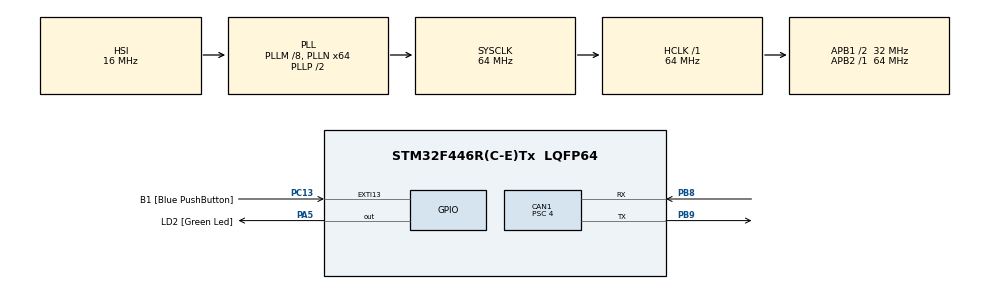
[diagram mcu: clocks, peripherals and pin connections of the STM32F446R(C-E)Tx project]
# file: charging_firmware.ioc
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CAN1.BS1=CAN_BS1_8TQ
CAN1.BS2=CAN_BS2_7TQ
CAN1.CalculateTimeBit=2000
CAN1.CalculateTimeQuantum=125.0
CAN1.Prescaler=4
Mcu.Family=STM32F4
Mcu.Name=STM32F446R(C-E)Tx
Mcu.Package=LQFP64
NVIC.CAN1_RX0_IRQn=true\:0\:0\:false\:false\:true\:true
NVIC.PriorityGroup=NVIC_PRIORITYGROUP_0
NVIC.TIM2_IRQn=true\:0\:0\:false\:false\:true\:true
PA13.GPIO_Label=TMS
PA13.Signal=SYS_JTMS-SWDIO
PA14.GPIO_Label=TCK
PA14.Signal=SYS_JTCK-SWCLK
PA2.GPIO_Label=USART_TX
PA2.Signal=USART2_TX
PA3.GPIO_Label=USART_RX
PA3.Signal=USART2_RX
PA5.GPIO_Label=LD2 [Green Led]
PA5.Signal=GPIO_Output
PB3.GPIO_Label=SWO
PB3.Signal=SYS_JTDO-SWO
PB8.Mode=Master
PB8.Signal=CAN1_RX
PB9.Mode=Master
PB9.Signal=CAN1_TX
PC13.GPIO_Label=B1 [Blue PushButton]
PC13.GPIO_ModeDefaultEXTI=GPIO_MODE_IT_FALLING
PC13.Signal=GPXTI13
PC14-OSC32_IN.Signal=RCC_OSC32_IN
PC15-OSC32_OUT.Signal=RCC_OSC32_OUT
PH0-OSC_IN.Signal=RCC_OSC_IN
PH1-OSC_OUT.Signal=RCC_OSC_OUT
ProjectManager.HeapSize=0x200
ProjectManager.StackSize=0x400
ProjectManager.TargetToolchain=SW4STM32
RCC.AHBFreq_Value=64000000
RCC.APB1CLKDivider=RCC_HCLK_DIV2
RCC.APB1Freq_Value=32000000
RCC.APB1TimFreq_Value=64000000
RCC.APB2Freq_Value=64000000
RCC.APB2TimFreq_Value=64000000
RCC.CortexFreq_Value=64000000
RCC.FLatency-AdvancedSettings=FLASH_LATENCY_2
RCC.HCLKFreq_Value=64000000
RCC.HSE_VALUE=8000000
RCC.HSI_VALUE=16000000
RCC.LSE_VALUE=32768
RCC.PLLM=8
RCC.PLLN=64
RCC.SYSCLKFreq_VALUE=64000000
RCC.SYSCLKSource=RCC_SYSCLKSOURCE_PLLCLK
RCC.USBFreq_Value=64000000
RCC.VCOOutputFreq_Value=128000000
TIM2.Period=49999
TIM2.Prescaler=6399
VP_TIM2_VS_ClockSourceINT.Mode=Internal
board=NUCLEO-F446RE

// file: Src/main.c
/**
  ******************************************************************************
  * File Name          : main.c
  * Description        : Main program body
  ******************************************************************************
  ** This notice applies to any and all portions of this file
  * that are not between comment pairs USER CODE BEGIN and
  * USER CODE END. Other portions of this file, whether
  * inserted by the user or by software development tools
  * are owned by their respective copyright owners.
  *
  * COPYRIGHT(c) 2017 STMicroelectronics
  *
  * Redistribution and use in source and binary forms, with or without modification,
  * are permitted provided that the following conditions are met:
  *   1. Redistributions of source code must retain the above copyright notice,
  *      this list of conditions and the following disclaimer.
  *   2. Redistributions in binary form must reproduce the above copyright notice,
  *      this list of conditions and the following disclaimer in the documentation
  *      and/or other materials provided with the distribution.
  *   3. Neither the name of STMicroelectronics nor the names of its contributors
  *      may be used to endorse or promote products derived from this software
  *      without specific prior written permission.
  *
  * THIS SOFTWARE IS PROVIDED BY THE COPYRIGHT HOLDERS AND CONTRIBUTORS "AS IS"
  * AND ANY EXPRESS OR IMPLIED WARRANTIES, INCLUDING, BUT NOT LIMITED TO, THE
  * IMPLIED WARRANTIES OF MERCHANTABILITY AND FITNESS FOR A PARTICULAR PURPOSE ARE
  * DISCLAIMED. IN NO EVENT SHALL THE COPYRIGHT HOLDER OR CONTRIBUTORS BE LIABLE
  * FOR ANY DIRECT, INDIRECT, INCIDENTAL, SPECIAL, EXEMPLARY, OR CONSEQUENTIAL
  * DAMAGES (INCLUDING, BUT NOT LIMITED TO, PROCUREMENT OF SUBSTITUTE GOODS OR
  * SERVICES; LOSS OF USE, DATA, OR PROFITS; OR BUSINESS INTERRUPTION) HOWEVER
  * CAUSED AND ON ANY THEORY OF LIABILITY, WHETHER IN CONTRACT, STRICT LIABILITY,
  * OR TORT (INCLUDING NEGLIGENCE OR OTHERWISE) ARISING IN ANY WAY OUT OF THE USE
  * OF THIS SOFTWARE, EVEN IF ADVISED OF THE POSSIBILITY OF SUCH DAMAGE.
  *
  ******************************************************************************
  */

#include "main.h"
#include "stm32f4xx_hal.h"

/* USER CODE BEGIN Includes */
#include "debug.h"
#include "can.h"
#include "temp.h"
/* USER CODE END Includes */

CAN_HandleTypeDef hcan1;

TIM_HandleTypeDef htim2;

/* USER CODE BEGIN PV */
/* Private variables ---------------------------------------------------------*/

/* USER CODE END PV */

void SystemClock_Config(void);
static void MX_GPIO_Init(void);
static void MX_CAN1_Init(void);
static void MX_TIM2_Init(void);

/* USER CODE BEGIN PFP */
/* Private function prototypes -----------------------------------------------*/

/* USER CODE END PFP */

int main(void)
{

  /* MCU Configuration----------------------------------------------------------*/

  /* Reset of all peripherals, Initializes the Flash interface and the Systick. */
  HAL_Init();

  /* Configure the system clock */
  SystemClock_Config();

  /* Initialize all configured peripherals */
  MX_GPIO_Init();
  MX_CAN1_Init();
  MX_TIM2_Init();

  /* USER CODE BEGIN 2 */
  debug_init();
  can_recieve_init();
  temp_init();
  /* USER CODE END 2 */

  /* Infinite loop */
  while (1)
  {

  /* USER CODE BEGIN 3 */
	  HAL_GPIO_TogglePin(LD2_GPIO_Port, LD2_Pin);
	  HAL_Delay(1000);
	  // can_test();
  }
  /* USER CODE END 3 */

}

/** System Clock Configuration
*/
void SystemClock_Config(void)
{

  RCC_OscInitTypeDef RCC_OscInitStruct;
  RCC_ClkInitTypeDef RCC_ClkInitStruct;

    /**Configure the main internal regulator output voltage
    */
  __HAL_RCC_PWR_CLK_ENABLE();

  __HAL_PWR_VOLTAGESCALING_CONFIG(PWR_REGULATOR_VOLTAGE_SCALE3);

    /**Initializes the CPU, AHB and APB busses clocks
    */
  RCC_OscInitStruct.OscillatorType = RCC_OSCILLATORTYPE_HSI;
  RCC_OscInitStruct.HSIState = RCC_HSI_ON;
  RCC_OscInitStruct.HSICalibrationValue = 16;
  RCC_OscInitStruct.PLL.PLLState = RCC_PLL_ON;
  RCC_OscInitStruct.PLL.PLLSource = RCC_PLLSOURCE_HSI;
  RCC_OscInitStruct.PLL.PLLM = 8;
  RCC_OscInitStruct.PLL.PLLN = 64;
  RCC_OscInitStruct.PLL.PLLP = RCC_PLLP_DIV2;
  RCC_OscInitStruct.PLL.PLLQ = 2;
  RCC_OscInitStruct.PLL.PLLR = 2;
  if (HAL_RCC_OscConfig(&RCC_OscInitStruct) != HAL_OK)
  {
    _Error_Handler(__FILE__, __LINE__);
  }

    /**Initializes the CPU, AHB and APB busses clocks
    */
  RCC_ClkInitStruct.ClockType = RCC_CLOCKTYPE_HCLK|RCC_CLOCKTYPE_SYSCLK
                              |RCC_CLOCKTYPE_PCLK1|RCC_CLOCKTYPE_PCLK2;
  RCC_ClkInitStruct.SYSCLKSource = RCC_SYSCLKSOURCE_PLLCLK;
  RCC_ClkInitStruct.AHBCLKDivider = RCC_SYSCLK_DIV1;
  RCC_ClkInitStruct.APB1CLKDivider = RCC_HCLK_DIV2;
  RCC_ClkInitStruct.APB2CLKDivider = RCC_HCLK_DIV1;

  if (HAL_RCC_ClockConfig(&RCC_ClkInitStruct, FLASH_LATENCY_2) != HAL_OK)
  {
    _Error_Handler(__FILE__, __LINE__);
  }

    /**Configure the Systick interrupt time
    */
  HAL_SYSTICK_Config(HAL_RCC_GetHCLKFreq()/1000);

    /**Configure the Systick
    */
  HAL_SYSTICK_CLKSourceConfig(SYSTICK_CLKSOURCE_HCLK);

  /* SysTick_IRQn interrupt configuration */
  HAL_NVIC_SetPriority(SysTick_IRQn, 0, 0);
}

/* CAN1 init function */
static void MX_CAN1_Init(void)
{

  hcan1.Instance = CAN1;
  hcan1.Init.Prescaler = 4;
  hcan1.Init.Mode = CAN_MODE_NORMAL;
  hcan1.Init.SJW = CAN_SJW_1TQ;
  hcan1.Init.BS1 = CAN_BS1_8TQ;
  hcan1.Init.BS2 = CAN_BS2_7TQ;
  hcan1.Init.TTCM = DISABLE;
  hcan1.Init.ABOM = DISABLE;
  hcan1.Init.AWUM = DISABLE;
  hcan1.Init.NART = DISABLE;
  hcan1.Init.RFLM = DISABLE;
  hcan1.Init.TXFP = DISABLE;
  if (HAL_CAN_Init(&hcan1) != HAL_OK)
  {
    _Error_Handler(__FILE__, __LINE__);
  }

}

/* TIM2 init function */
static void MX_TIM2_Init(void)
{

  TIM_ClockConfigTypeDef sClockSourceConfig;
  TIM_MasterConfigTypeDef sMasterConfig;

  htim2.Instance = TIM2;
  htim2.Init.Prescaler = 6399;
  htim2.Init.CounterMode = TIM_COUNTERMODE_UP;
  htim2.Init.Period = 49999;
  htim2.Init.ClockDivision = TIM_CLOCKDIVISION_DIV1;
  if (HAL_TIM_Base_Init(&htim2) != HAL_OK)
  {
    _Error_Handler(__FILE__, __LINE__);
  }

  sClockSourceConfig.ClockSource = TIM_CLOCKSOURCE_INTERNAL;
  if (HAL_TIM_ConfigClockSource(&htim2, &sClockSourceConfig) != HAL_OK)
  {
    _Error_Handler(__FILE__, __LINE__);
  }

  sMasterConfig.MasterOutputTrigger = TIM_TRGO_RESET;
  sMasterConfig.MasterSlaveMode = TIM_MASTERSLAVEMODE_DISABLE;
  if (HAL_TIMEx_MasterConfigSynchronization(&htim2, &sMasterConfig) != HAL_OK)
  {
    _Error_Handler(__FILE__, __LINE__);
  }

}

/** Configure pins as
        * Analog
        * Input
        * Output
        * EVENT_OUT
        * EXTI
     PA2   ------> USART2_TX
     PA3   ------> USART2_RX
*/
static void MX_GPIO_Init(void)
{

  GPIO_InitTypeDef GPIO_InitStruct;

  /* GPIO Ports Clock Enable */
  __HAL_RCC_GPIOC_CLK_ENABLE();
  __HAL_RCC_GPIOH_CLK_ENABLE();
  __HAL_RCC_GPIOA_CLK_ENABLE();
  __HAL_RCC_GPIOB_CLK_ENABLE();

  /*Configure GPIO pin Output Level */
  HAL_GPIO_WritePin(LD2_GPIO_Port, LD2_Pin, GPIO_PIN_RESET);

  /*Configure GPIO pin : B1_Pin */
  GPIO_InitStruct.Pin = B1_Pin;
  GPIO_InitStruct.Mode = GPIO_MODE_IT_FALLING;
  GPIO_InitStruct.Pull = GPIO_NOPULL;
  HAL_GPIO_Init(B1_GPIO_Port, &GPIO_InitStruct);

  /*Configure GPIO pins : USART_TX_Pin USART_RX_Pin */
  GPIO_InitStruct.Pin = USART_TX_Pin|USART_RX_Pin;
  GPIO_InitStruct.Mode = GPIO_MODE_AF_PP;
  GPIO_InitStruct.Pull = GPIO_NOPULL;
  GPIO_InitStruct.Speed = GPIO_SPEED_FREQ_VERY_HIGH;
  GPIO_InitStruct.Alternate = GPIO_AF7_USART2;
  HAL_GPIO_Init(GPIOA, &GPIO_InitStruct);

  /*Configure GPIO pin : LD2_Pin */
  GPIO_InitStruct.Pin = LD2_Pin;
  GPIO_InitStruct.Mode = GPIO_MODE_OUTPUT_PP;
  GPIO_InitStruct.Pull = GPIO_NOPULL;
  GPIO_InitStruct.Speed = GPIO_SPEED_FREQ_LOW;
  HAL_GPIO_Init(LD2_GPIO_Port, &GPIO_InitStruct);

}

void _Error_Handler(char * file, int line)
{
  /* USER CODE BEGIN Error_Handler_Debug */
  /* User can add his own implementation to report the HAL error return state */
  HAL_GPIO_WritePin(LD2_GPIO_Port, LD2_Pin, GPIO_PIN_SET);
  while(1)
  {
  }
  /* USER CODE END Error_Handler_Debug */
}

/************************ (C) COPYRIGHT STMicroelectronics *****END OF FILE****/
